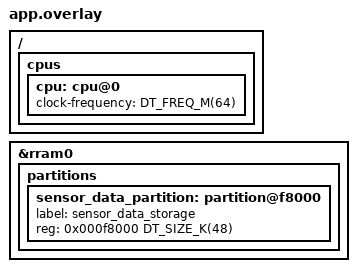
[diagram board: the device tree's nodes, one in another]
/*
 * Copyright (c) 2023 Nordic Semiconductor ASA
 *
 * SPDX-License-Identifier: LicenseRef-Nordic-5-Clause
 */

/ {
	cpus {
		cpu: cpu@0 {
			/* Temporary change to 64Mhz.
			 * Will be fixed by:
			 * NRFX-3331
			 * NRFX-4580
			 */
			clock-frequency = <DT_FREQ_M(64)>;
		};
	};
};

&rram0 {
	partitions {
		sensor_data_partition: partition@f8000 {
			label = "sensor_data_storage";
			reg = <0x000f8000 DT_SIZE_K(48)>;
		};
	};
};
